AUTOSAR XML (schema 4-0-3)
standard types defined: sint32, uint32, uint8
package /Swcs/BT_Swcs/IDTs
  6 x impl type, all with category=VALUE:
    Current_s32: base-type=sint32
    ErrorCode_u32: base-type=uint32
    GenericByte: base-type=uint8
    OnOff: base-type=uint8, compu {0=OFF, 255=ON, else OFF}
    Power_s32: base-type=sint32
    Voltage_s32: base-type=sint32
package /Swcs/BT_Swcs/SCI_Pfc
  bsw module description BswSCI_Pfc: category=BSW_MODULE, module-id=255, provided-entrys=[pfc_BswMainFunction, Pfc_Init, Pfc_DeInit]
    bsw internal behavior InternalBehavior
      bsw schedulable entity pfc_BswMainFunction: implemented-entry=pfc_BswMainFunction
      bsw called entity Pfc_Init: implemented-entry=Pfc_Init
      bsw called entity Pfc_DeInit: implemented-entry=Pfc_DeInit
      bsw timing event PFC_Bsw_10ms_te: starts-on-event=pfc_BswMainFunction, period=0.01
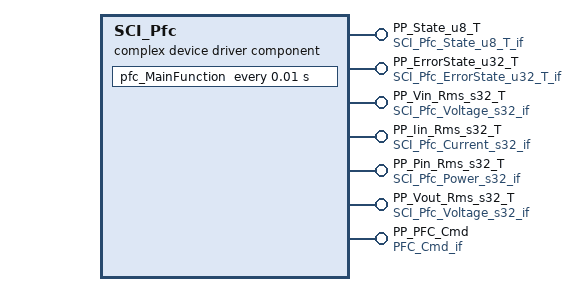
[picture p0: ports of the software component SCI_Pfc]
  complex device driver sw component type SCI_Pfc  # This component (SCI_Pfc) implements the Interface version 1.0.0
    7 x provide port:
      PP_State_u8_T: nonqueued-sender-com-spec{data-element=SCI_Pfc_State_u8_TValue, init-value=0}, provided-interface=SCI_Pfc_State_u8_T_if  # Description: Pfc state variable
      PP_ErrorState_u32_T: nonqueued-sender-com-spec{data-element=SCI_Pfc_ErrorState_u32_TValue, init-value=0}, provided-interface=SCI_Pfc_ErrorState_u32_T_if  # Description: Error State bitfields
      PP_Vin_Rms_s32_T: nonqueued-sender-com-spec{data-element=SCI_Pfc_Voltage_s32Value, init-value=0}, provided-interface=SCI_Pfc_Voltage_s32_if  # Description: Input Voltage, RMS value
      PP_Iin_Rms_s32_T: nonqueued-sender-com-spec{data-element=SCI_Pfc_Current_s32Value, init-value=0}, provided-interface=SCI_Pfc_Current_s32_if  # Description: Input Current, RMS value
      PP_Pin_Rms_s32_T: nonqueued-sender-com-spec{data-element=SCI_Pfc_Power_s32Value, init-value=0}, provided-interface=SCI_Pfc_Power_s32_if  # Description: Input Power, RMS value
      PP_Vout_Rms_s32_T: nonqueued-sender-com-spec{data-element=SCI_Pfc_Voltage_s32Value, init-value=0}, provided-interface=SCI_Pfc_Voltage_s32_if  # Description: Output Voltage, RMS value
      PP_PFC_Cmd: provided-interface=PFC_Cmd_if  # Description: Command interface By Turn ON / OFF command, the signal IoHwAbs_Enable_AFE_b_T should be driven
        provided-com-specs:
          operation=Turn, queue-length=1
          operation=SetVoltage, queue-length=1
          operation=ClearFaults, queue-length=1
    behavior SCI_Pfc_Swc_IB: category=CDD_SWC_IB, data-type-mapping=SCI_Pfc_DataMapping, handle-termination-and-restart=NO-SUPPORT
      timing event PFC_Rte_10ms_te: start-on-event=pfc_MainFunction, period=0.01
      operation invoked event PFC_Cmd_onTurn_oie: start-on-event=PFC_Cmd_Turn, operation=PP_PFC_Cmd.Turn
      operation invoked event PFC_Cmd_onSetVoltage_oie: start-on-event=PFC_Cmd_SetVoltage, operation=PP_PFC_Cmd.SetVoltage
      operation invoked event PFC_Cmd_onClearFaults_oie: start-on-event=PFC_Cmd_ClearFaults, operation=PP_PFC_Cmd.ClearFaults
      4 x runnable:
        pfc_MainFunction
          data-write-access:
            6 x access:
              DWA_PP_State_u8_T_SCI_Pfc_State_u8_TValue: accessed-variable=PP_State_u8_T.SCI_Pfc_State_u8_TValue
              DWA_PP_ErrorState_u32_T_SCI_Pfc_ErrorState_u32_TValue: accessed-variable=PP_ErrorState_u32_T.SCI_Pfc_ErrorState_u32_TValue
              DWA_PP_Vin_Rms_s32_T_SCI_Pfc_Voltage_s32Value: accessed-variable=PP_Vin_Rms_s32_T.SCI_Pfc_Voltage_s32Value
              DWA_PP_Iin_Rms_s32_T_SCI_Pfc_Current_s32Value: accessed-variable=PP_Iin_Rms_s32_T.SCI_Pfc_Current_s32Value
              DWA_PP_Pin_Rms_s32_T_SCI_Pfc_Power_s32Value: accessed-variable=PP_Pin_Rms_s32_T.SCI_Pfc_Power_s32Value
              DWA_PP_Vout_Rms_s32_T_SCI_Pfc_Voltage_s32Value: accessed-variable=PP_Vout_Rms_s32_T.SCI_Pfc_Voltage_s32Value
        PFC_Cmd_Turn: runnable-entity-argument=symbol=aValue
        PFC_Cmd_SetVoltage: runnable-entity-argument=symbol=aValue
        PFC_Cmd_ClearFaults: runnable-entity-argument=symbol=aMask
  bsw implementation SCI_Pfc_BswImpl: programming-language=C, sw-version=1.0.0, swc-bsw-mapping=cddBswSwc_mapping, vendor-id=999, ar-release-version=4.0.3, behavior=InternalBehavior
    code-descriptors:
      code SRC: artifact-descriptors=autosar-engineering-object={short-label=EngObject, category=SWSRC}
    resource consumption Resources
      memory section CODE: sw-addrmethod=SCI_Pfc_SwAddrMethod
  sw addr method SCI_Pfc_SwAddrMethod: memory-allocation-keyword-policy=ADDR-METHOD-SHORT-NAME, section-type=CODE
  swc implementation SCI_Pfc_SwcImpl: programming-language=C, sw-version=1.0.0, vendor-id=999, behavior=SCI_Pfc_Swc_IB
    code-descriptors:
      code SRC: artifact-descriptors=autosar-engineering-object={short-label=EngObject, category=SWSRC}
    resource consumption Resources
  swc bsw mapping cddBswSwc_mapping: bsw-behavior=InternalBehavior, swc-behavior=SCI_Pfc_Swc_IB
package /Swcs/BT_Swcs/SCI_Pfc/ADTs
  6 x app type, all with category=VALUE:
    SCI_Pfc_Current_s32_adt
    SCI_Pfc_ErrorState_u32_T_adt
    SCI_Pfc_OnOff_adt
    SCI_Pfc_Power_s32_adt
    SCI_Pfc_State_u8_T_adt
    SCI_Pfc_Voltage_s32_adt
package /Swcs/BT_Swcs/SCI_Pfc/Calls
  bsw module entry Pfc_DeInit: category=REGULAR_CALL, service-id=2, role=Pfc_deinitialisation, is-reentrant=false, is-synchronous=false, call-type=REGULAR, execution-context=HOOK, sw-service-impl-policy=STANDARD
  bsw module entry Pfc_Init: category=REGULAR_CALL, service-id=2, role=Pfc_initialisation, is-reentrant=false, is-synchronous=false, call-type=REGULAR, execution-context=HOOK, sw-service-impl-policy=STANDARD
package /Swcs/BT_Swcs/SCI_Pfc/Consts
  6 x constant specification, all with value-spec=0:
    SCI_Pfc_Current_s32_adt_const
    SCI_Pfc_ErrorState_u32_T_adt_const
    SCI_Pfc_OnOff_adt_const
    SCI_Pfc_Power_s32_adt_const
    SCI_Pfc_State_u8_T_adt_const
    SCI_Pfc_Voltage_s32_adt_const
package /Swcs/BT_Swcs/SCI_Pfc/DataTypeMappingSets
  data type mapping set SCI_Pfc_DataMapping
    data-type-maps:
      application-data-type=SCI_Pfc_State_u8_T_adt, implementation-data-type=GenericByte
      application-data-type=SCI_Pfc_ErrorState_u32_T_adt, implementation-data-type=ErrorCode_u32
      application-data-type=SCI_Pfc_OnOff_adt, implementation-data-type=OnOff
      application-data-type=SCI_Pfc_Voltage_s32_adt, implementation-data-type=Voltage_s32
      application-data-type=SCI_Pfc_Current_s32_adt, implementation-data-type=Current_s32
      application-data-type=SCI_Pfc_Power_s32_adt, implementation-data-type=Power_s32
package /Swcs/BT_Swcs/SCI_Pfc/IFs
  client server interface PFC_Cmd_if: is-service=true
    operation Turn: possible-error=[E_BUSY, E_ERROR]  # aValue: 0 --> Turning OFF aValue: 1 --> Turning ON
      arg aValue: type=OnOff, direction=IN, server-argument-impl-policy=USE-ARGUMENT-TYPE
    operation SetVoltage: possible-error=[E_BUSY, E_ERROR]
      arg aValue: type=Voltage_s32, direction=IN, server-argument-impl-policy=USE-ARGUMENT-TYPE
    operation ClearFaults: possible-error=[E_BUSY, E_ERROR]  # 0xffffffff for clearing each and any fault
      arg aMask: type=ErrorCode_u32, direction=IN, server-argument-impl-policy=USE-ARGUMENT-TYPE
    error E_ERROR: error-code=1
    error E_BUSY: error-code=2
  5 x sender receiver interface:
    SCI_Pfc_Current_s32_if
      data SCI_Pfc_Current_s32Value: type=Current_s32
    SCI_Pfc_ErrorState_u32_T_if
      data SCI_Pfc_ErrorState_u32_TValue: type=ErrorCode_u32
    SCI_Pfc_Power_s32_if
      data SCI_Pfc_Power_s32Value: type=Power_s32
    SCI_Pfc_State_u8_T_if
      data SCI_Pfc_State_u8_TValue: type=GenericByte
    SCI_Pfc_Voltage_s32_if
      data SCI_Pfc_Voltage_s32Value: type=Voltage_s32
package /Swcs/BT_Swcs/SCI_Pfc/Runnables
  bsw module entry pfc_BswMainFunction: category=RUNNABLE, service-id=1, role=pfc_BswMainFunction, is-reentrant=false, is-synchronous=true, call-type=SCHEDULED, execution-context=TASK, sw-service-impl-policy=STANDARD
